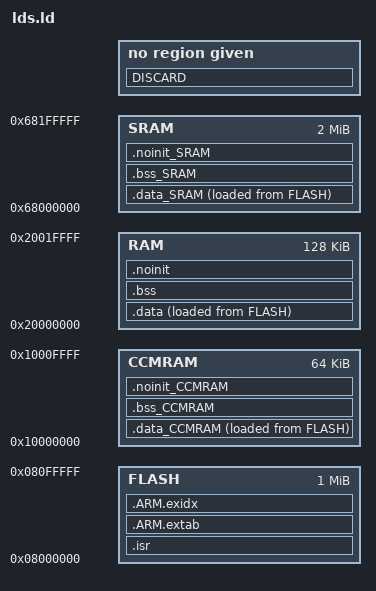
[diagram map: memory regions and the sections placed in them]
OUTPUT_FORMAT(elf32-littlearm)
OUTPUT_ARCH(arm)
ENTRY(_start)

MEMORY
{
    FLASH   : ORIGIN = 0x08000000,	LENGTH = 1M
    RAM     : ORIGIN = 0x20000000,	LENGTH = 128K
    CCMRAM  : ORIGIN = 0x10000000, 	LENGTH = 64K 
    SRAM    : ORIGIN = 0x68000000,	LENGTH = 2M
}

__Main_Stack_Size = 1024 ; 	/* 栈大小为1024 Byte */

__stack = ORIGIN(RAM) + LENGTH(RAM);

_estack = __stack; 	/* STM specific definition 此处栈顶指针为0x2002 0000 */

SECTIONS
{
    .isr : ALIGN(4)
    {
        FILL(0xFF)
        
        __vectors_start = .;
        KEEP(*(.isr_vector))     		/* Interrupt vectors */
		*(.after_vectors .after_vectors.*)	/* Startup code and ISR */
		
        __data_regions_array_start = .;
        
        LONG(LOADADDR(.data));
        LONG(ADDR(.data));
        LONG(ADDR(.data)+SIZEOF(.data));
        
        LONG(LOADADDR(.data_CCMRAM));
        LONG(ADDR(.data_CCMRAM));
        LONG(ADDR(.data_CCMRAM)+SIZEOF(.data_CCMRAM));
        
        LONG(LOADADDR(.data_SRAM));
	    LONG(ADDR(.data_SRAM));
	    LONG(ADDR(.data_SRAM)+SIZEOF(.data_SRAM));
        
        __data_regions_array_end = .;
        
        __bss_regions_array_start = .;
        
        LONG(ADDR(.bss));
        LONG(ADDR(.bss)+SIZEOF(.bss));
        
        LONG(ADDR(.bss_CCMRAM));
        LONG(ADDR(.bss_CCMRAM)+SIZEOF(.bss_CCMRAM));
        
        LONG(ADDR(.bss_SRAM));
        LONG(ADDR(.bss_SRAM)+SIZEOF(.bss_SRAM));
        
        __bss_regions_array_end = .;
        
        *(.flashtext .flashtext.*)
        *(.text .text.*) 
        *(.rodata .rodata.* .constdata .constdata.*)   
        
		/*
		 * Stub sections generated by the linker, to glue together 
		 * ARM and Thumb code. .glue_7 is used for ARM code calling 
		 * Thumb code, and .glue_7t is used for Thumb code calling 
		 * ARM code. Apparently always generated by the linker, for some
		 * architectures, so better leave them here.
		 */
        *(.glue_7)
        *(.glue_7t)
    } >FLASH
       
    /* ARM magic sections */
	.ARM.extab : ALIGN(4)
   	{
       *(.ARM.extab* .gnu.linkonce.armextab.*)
   	} > FLASH
   	
    . = ALIGN(4);
   	__exidx_start = .;   	
   	.ARM.exidx : ALIGN(4)
   	{
       *(.ARM.exidx* .gnu.linkonce.armexidx.*)
   	} > FLASH
   	
	__exidx_end = .;
   	
    . = ALIGN(4);
    _etext = .;
    __etext = .;
    
    /*64K 内部CCMRAM 的data段*/
    .data_CCMRAM : ALIGN(4)
    {
       FILL(0xFF)
       *(.data.ccrram .data.ccrram.*)
       . = ALIGN(4) ;
    } > CCMRAM AT>FLASH
    
    /*2M 外部SRAM 的data段*/
    .data_SRAM : ALIGN(4)
    {
       FILL(0xFF)
       *(.data.hk .data.hk.*)
       . = ALIGN(4) ;
    } > SRAM AT>FLASH
    
    .data : 
    { 
    	FILL(0xFF)
        _sdata = .; 
        __data_start__ = . ;
        
        *(.data .data.*) 
        . = ALIGN(4); 
        
        PROVIDE (__command_start = .);
		*(.commands);
		PROVIDE (__command_end = .);
		. = ALIGN(4);
    		
		__ram_persist_start = .;
		*(.ram_persist);
		__ram_persist_end = .;
        . = ALIGN(4); 
        
        _edata = . ; 
        __data_end__ = . ; 
    } > RAM AT >FLASH
    
	.bss_CCMRAM (NOLOAD) : ALIGN(4)
	{
		*(.bss.ccmram .bss.ccmram.*)
	} > CCMRAM
	
	.bss_SRAM (NOLOAD) : ALIGN(4)
	{
		*(.bss.hk .bss.hk.*)
	} > SRAM

    .bss (NOLOAD) : 
    { 
	 	__bss_start__ = .; 
        _sbss = . ; 
        
        *(.bss .bss.*) 
        *(COMMON) 
        . = ALIGN(4); 
        
        __bss_end__ = .; 
        _ebss = . ; 
    } > RAM
    
    .noinit_CCMRAM (NOLOAD) : ALIGN(4)
    {
        *(.noinit.ccrram .noinit.ccrram.*)         
    } > CCMRAM
    
    .noinit_SRAM (NOLOAD) : ALIGN(4)
    {
        *(.noinit.hk .noinit.hk.*)         
    } > SRAM  
    
    .noinit (NOLOAD) : ALIGN(4)
    {
        _noinit = .;
        
        *(.noinit .noinit.*) 
        
        . = ALIGN(4) ;
        _end_noinit = .;   
    } > RAM
    
    __heap_start__ = .;
    __heap_limit__ = __stack - __Main_Stack_Size;
    
    /* Mandatory to be word aligned, _sbrk assumes this */
    PROVIDE ( end = _end_noinit ); /* was _ebss */
    PROVIDE ( _end = _end_noinit );
    PROVIDE ( __end = _end_noinit );
    PROVIDE ( __end__ = _end_noinit );
    
    DISCARD :
	{
		libc.a ( * )
	    libm.a ( * )
	    libgcc.a ( * )
	}	  
	
    /* Stabs debugging sections.  */
    .stab          0 : { *(.stab) }
    .stabstr       0 : { *(.stabstr) }
    .stab.excl     0 : { *(.stab.excl) }
    .stab.exclstr  0 : { *(.stab.exclstr) }
    .stab.index    0 : { *(.stab.index) }
    .stab.indexstr 0 : { *(.stab.indexstr) }
    .comment       0 : { *(.comment) }
    /*
     * DWARF debug sections.
     * Symbols in the DWARF debugging sections are relative to the beginning
     * of the section so we begin them at 0.  
     */
    /* DWARF 1 */
    .debug          0 : { *(.debug) }
    .line           0 : { *(.line) }
    /* GNU DWARF 1 extensions */
    .debug_srcinfo  0 : { *(.debug_srcinfo) }
    .debug_sfnames  0 : { *(.debug_sfnames) }
    /* DWARF 1.1 and DWARF 2 */
    .debug_aranges  0 : { *(.debug_aranges) }
    .debug_pubnames 0 : { *(.debug_pubnames) }
    /* DWARF 2 */
    .debug_info     0 : { *(.debug_info .gnu.linkonce.wi.*) }
    .debug_abbrev   0 : { *(.debug_abbrev) }
    .debug_line     0 : { *(.debug_line) }
    .debug_frame    0 : { *(.debug_frame) }
    .debug_str      0 : { *(.debug_str) }
    .debug_loc      0 : { *(.debug_loc) }
    .debug_macinfo  0 : { *(.debug_macinfo) }
    /* SGI/MIPS DWARF 2 extensions */
    .debug_weaknames 0 : { *(.debug_weaknames) }
    .debug_funcnames 0 : { *(.debug_funcnames) }
    .debug_typenames 0 : { *(.debug_typenames) }
    .debug_varnames  0 : { *(.debug_varnames) }
}
    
